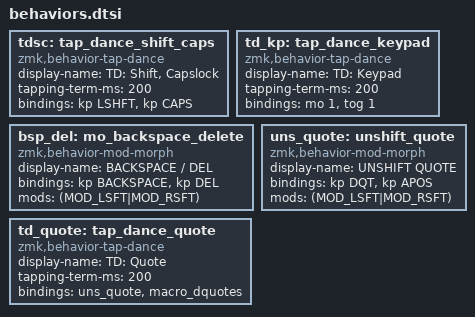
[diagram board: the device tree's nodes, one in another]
tdsc: tap_dance_shift_caps {
    compatible = "zmk,behavior-tap-dance";
    display-name = "TD: Shift, Capslock";
    #binding-cells = <0>;
    tapping-term-ms = <200>;
    bindings = <&kp LSHFT>, <&kp CAPS>;
};

td_kp: tap_dance_keypad {
    compatible = "zmk,behavior-tap-dance";
    display-name = "TD: Keypad";
    #binding-cells = <0>;
    tapping-term-ms = <200>;
    bindings = <&mo 1>, <&tog 1>;
};

bsp_del: mo_backspace_delete {
    compatible = "zmk,behavior-mod-morph";
    display-name = "BACKSPACE / DEL";
    bindings = <&kp BACKSPACE>, <&kp DEL>;

    #binding-cells = <0>;
    mods = <(MOD_LSFT|MOD_RSFT)>;
};

// Double quotes
uns_quote: unshift_quote {
  compatible = "zmk,behavior-mod-morph";
  display-name = "UNSHIFT QUOTE";
  bindings = <&kp DQT>, <&kp APOS>;
  #binding-cells = <0>;
  mods = <(MOD_LSFT|MOD_RSFT)>;
};
td_quote: tap_dance_quote {
    compatible = "zmk,behavior-tap-dance";
    display-name = "TD: Quote";
    #binding-cells = <0>;
    tapping-term-ms = <200>;
    bindings = <&uns_quote>, <&macro_dquotes>;
};
